# M1AGL register map
Vendor: Microsemi; Series: IGLOO
Cortex-M1 on IGLOO FPGA
CPU: CM1, little endian
Registers are 32-bit, read-write, reset 0x0 unless marked. A register's access mark holds for its fields unless they carry their own. Offsets are from the block's base; lines under a group give offsets from that group; [hi:lo] are bit positions; {n}, {i} and the like mark numbered series; 'fields as' and 'values as' point back to an identical list; <NAME> marks a mode.

## Memory map
0xA1000000 CoreUARTapb size 0x1000 — serial communication controller with a flexible serial data interface
0xA2000000 CoreTimer size 0x1000 — interrupt-generating, programmable decrementing counter
0xA3000000 CoreInterrupt size 0x1000 — Flexible Interrupt Controller for Advanced Microcontroller Bus Architecture (AMBA) Based Systems

## Interrupts
1 Core_Timer_Interrupt (CoreUARTapb, CoreTimer)

## CoreUARTapb — serial communication controller with a flexible serial data interface
Base 0xA1000000
0x00 Tx_Data — Transmit Data register
  [7:0] Value
0x04 Rx_Data — Receive Data register
  [7:0] Value
0x08 Control_1 — Control register 1
  [7:0] Baud_Value
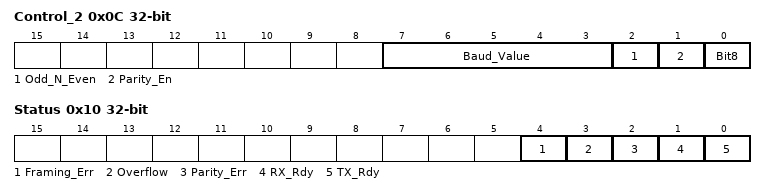
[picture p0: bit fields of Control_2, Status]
0x0C Control_2 — Control register 1
  [7:3] Baud_Value
  [2] Odd_N_Even
    0=Even; 1=Odd
  [1] Parity_En
  [0] Bit8
0x10 Status — Control register 1
  [4] Framing_Err, [3] Overflow, [2] Parity_Err, [1] RX_Rdy, [0] TX_Rdy
0x14 Control_3 — Control register 1
  [2:0] Baud_Val_Fraction

## CoreTimer — interrupt-generating, programmable decrementing counter
Base 0xA2000000
0x00 Load_Value — Counter load value
0x04 Current_Value — Counter current value
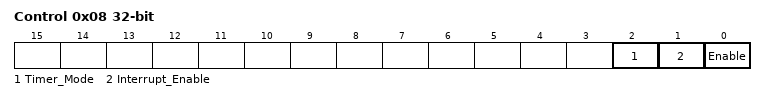
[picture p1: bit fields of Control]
0x08 Control — PWM Configuration Register.
  [2] Timer_Mode
    0=Continuous; 1=One_Shot
  [1] Interrupt_Enable
  [0] Enable
0x0C Prescale — Clock prescale setting
  [3:0] Value
    0=Divide_By_2; 1=Divide_By_4; 2=Divide_By_8; 3=Divide_By_16; 4=Divide_By_32; 5=Divide_By_64; 6=Divide_By_128; 7=Divide_By_256; 8=Divide_By_512; 9=Divide_By_1024
0x10 Interrupt_Clear — Interrupt Clear. Any write to this register will clear the interrupt.
0x14 Raw_Interrupt_Status — PWM Configuration Register.
  [0] Pending
0x18 Masked_Interrupt_Status — PWM Configuration Register.
  [0] Pending

## CoreInterrupt — Flexible Interrupt Controller for Advanced Microcontroller Bus Architecture (AMBA) Based Systems
Base 0xA3000000
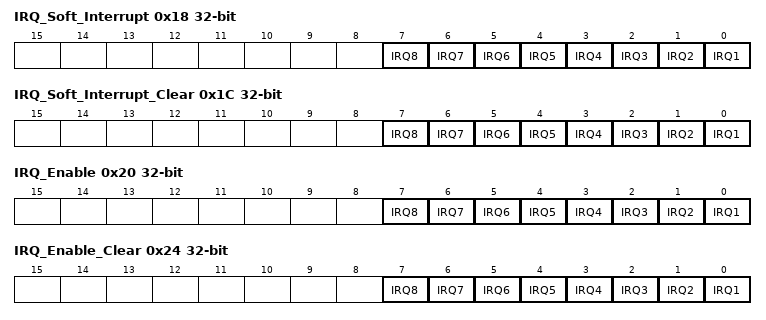
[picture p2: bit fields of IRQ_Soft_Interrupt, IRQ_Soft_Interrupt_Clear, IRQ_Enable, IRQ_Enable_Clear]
0x18 IRQ_Soft_Interrupt — Software interrupt trigger IRQs.
  [n-1] IRQ{n} (n=1..8)
0x1C IRQ_Soft_Interrupt_Clear — Clear soft IRQs.
  [n-1] IRQ{n} (n=1..8)
0x20 IRQ_Enable — Enable IRQs.
  [n-1] IRQ{n} (n=1..8)
0x24 IRQ_Enable_Clear — Disable IRQs.
  [n-1] IRQ{n} (n=1..8)
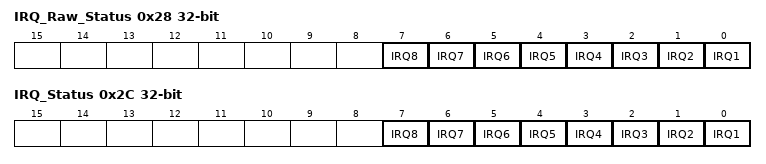
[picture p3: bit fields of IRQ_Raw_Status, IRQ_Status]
0x28 IRQ_Raw_Status
  [n-1] IRQ{n} (n=1..8)
0x2C IRQ_Status
  [n-1] IRQ{n} (n=1..8)
